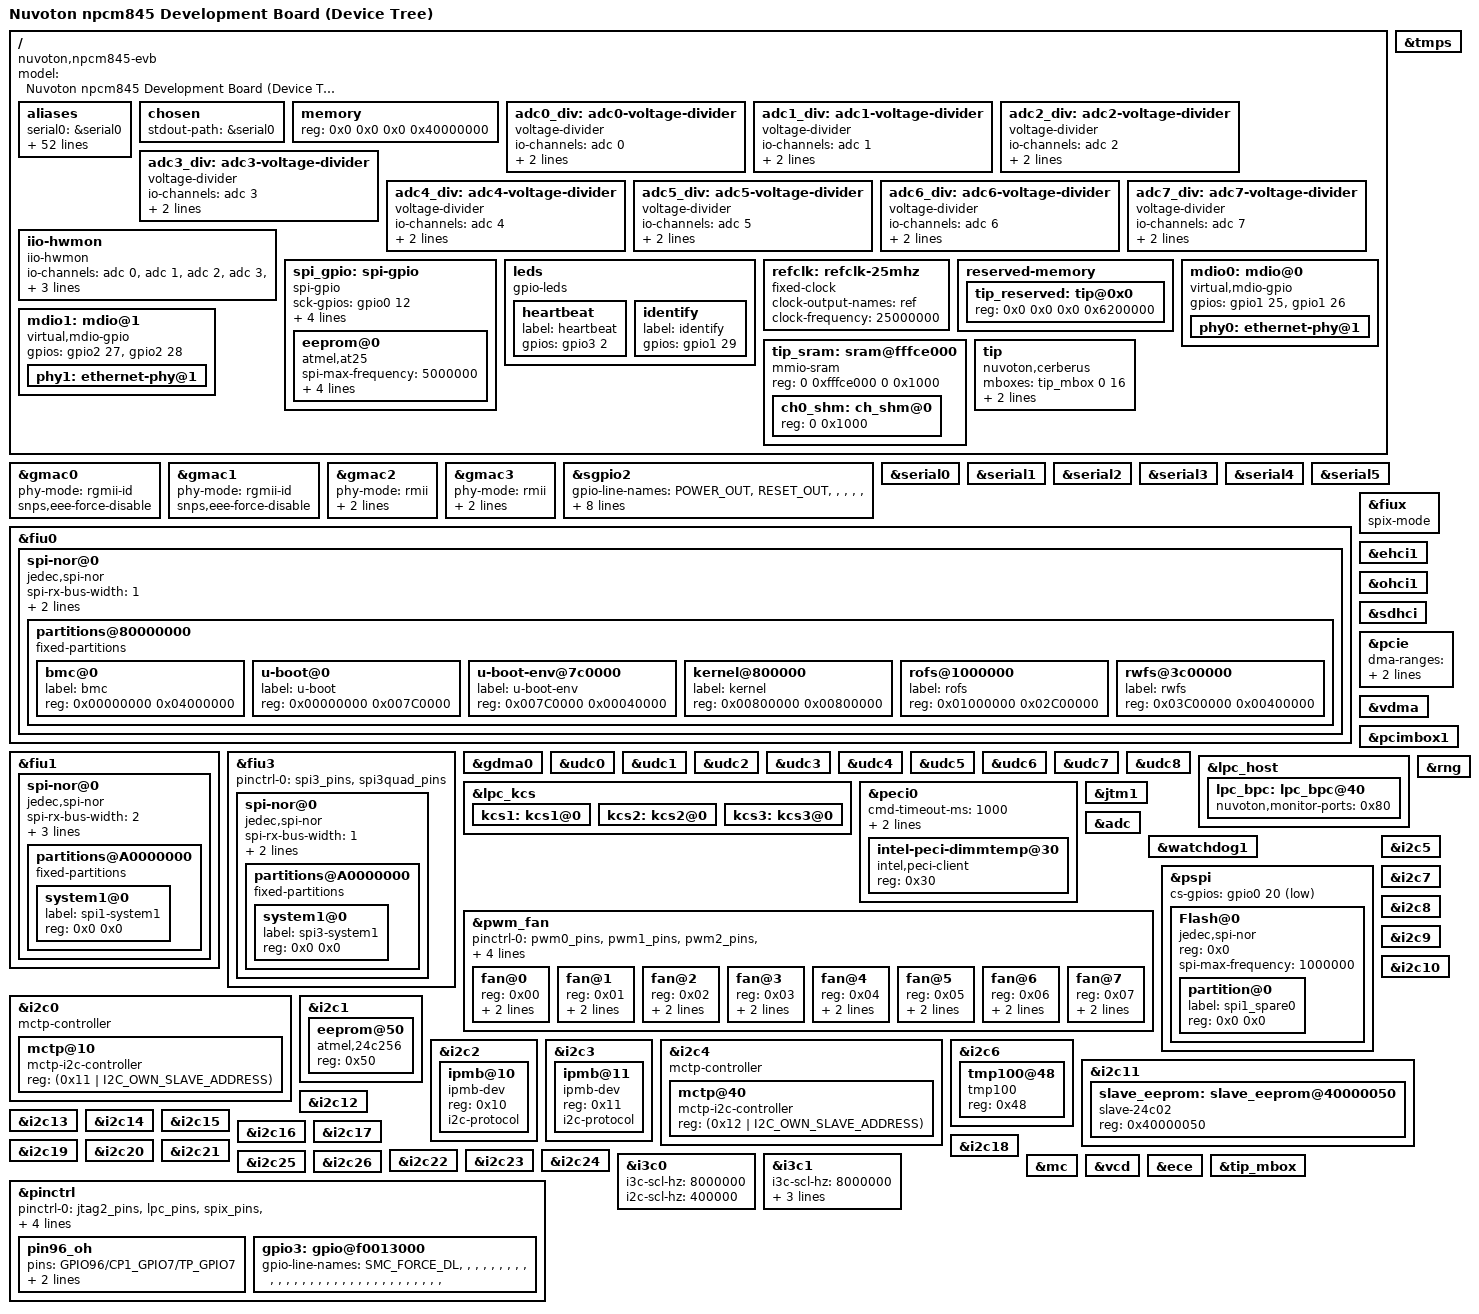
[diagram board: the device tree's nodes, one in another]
// SPDX-License-Identifier: GPL-2.0
// Copyright (c) 2021 Nuvoton Technology tomer.maimon@nuvoton.com

/dts-v1/;
#include "nuvoton-npcm845.dtsi"
#include "nuvoton-npcm845-pincfg-evb.dtsi"
#include <dt-bindings/i2c/i2c.h>

/ {
	model = "Nuvoton npcm845 Development Board (Device Tree)";
	compatible = "nuvoton,npcm845-evb", "nuvoton,npcm845";

	aliases {
		serial0 = &serial0;
		serial1 = &serial1;
		serial2 = &serial2;
		serial3 = &serial3;
		serial4 = &serial4;
		serial5 = &serial5;
		ethernet0 = &gmac0;
		ethernet1 = &gmac1;
		ethernet2 = &gmac2;
		ethernet3 = &gmac3;
		mdio-gpio0 = &mdio0;
		mdio-gpio1 = &mdio1;
		udc0 = &udc0;
		udc1 = &udc1;
		udc2 = &udc2;
		udc3 = &udc3;
		udc4 = &udc4;
		udc5 = &udc5;
		udc6 = &udc6;
		udc7 = &udc7;
		udc8 = &udc8;
		fiu0 = &fiu0;
		fiu1 = &fiu3;
		fiu2 = &fiux;
		fiu3 = &fiu1;
		i2c0 = &i2c0;
		i2c1 = &i2c1;
		i2c2 = &i2c2;
		i2c3 = &i2c3;
		i2c4 = &i2c4;
		i2c5 = &i2c5;
		i2c6 = &i2c6;
		i2c7 = &i2c7;
		i2c8 = &i2c8;
		i2c9 = &i2c9;
		i2c10 = &i2c10;
		i2c11 = &i2c11;
		i2c12 = &i2c12;
		i2c13 = &i2c13;
		i2c14 = &i2c14;
		i2c15 = &i2c15;
		i2c16 = &i2c16;
		i2c17 = &i2c17;
		i2c18 = &i2c18;
		i2c19 = &i2c19;
		i2c20 = &i2c20;
		i2c21 = &i2c21;
		i2c22 = &i2c22;
		i2c23 = &i2c23;
		i2c24 = &i2c24;
		i2c25 = &i2c25;
		i2c26 = &i2c26;
		spi1 = &spi_gpio;
	};

	chosen {
		stdout-path = &serial0;
	};

	memory {
		reg = <0x0 0x0 0x0 0x40000000>;
	};

	/*
	 * Voltage dividers for ADC channels.
	 * Adjust output-ohms and full-ohms according to your schematic.
	 * Formula: Vin = Vout × (full-ohms / output-ohms)
	 *
	 * Example: If R1 = 100K, R2 = 10K (10:1 divider)
	 *   output-ohms = 10000  (R2, resistor to GND)
	 *   full-ohms = 110000   (R1 + R2)
	 */
	adc0_div: adc0-voltage-divider {
		compatible = "voltage-divider";
		io-channels = <&adc 0>;
		io-channel-names = "parent";
		#io-channel-cells = <0>;
		output-ohms = <4700>;
		full-ohms = <104700>;
	};

	adc1_div: adc1-voltage-divider {
		compatible = "voltage-divider";
		io-channels = <&adc 1>;
		io-channel-names = "parent";
		#io-channel-cells = <0>;
		output-ohms = <10000>;
		full-ohms = <110000>;
	};

	adc2_div: adc2-voltage-divider {
		compatible = "voltage-divider";
		io-channels = <&adc 2>;
		io-channel-names = "parent";
		#io-channel-cells = <0>;
		output-ohms = <2000>;
		full-ohms = <12000>;
	};

	adc3_div: adc3-voltage-divider {
		compatible = "voltage-divider";
		io-channels = <&adc 3>;
		io-channel-names = "parent";
		#io-channel-cells = <0>;
		output-ohms = <4700>;
		full-ohms = <14700>;
	};

	adc4_div: adc4-voltage-divider {
		compatible = "voltage-divider";
		io-channels = <&adc 4>;
		io-channel-names = "parent";
		#io-channel-cells = <0>;
		output-ohms = <10000>;
		full-ohms = <14700>;
	};

	adc5_div: adc5-voltage-divider {
		compatible = "voltage-divider";
		io-channels = <&adc 5>;
		io-channel-names = "parent";
		#io-channel-cells = <0>;
		output-ohms = <10000>;
		full-ohms = <12000>;
	};

	adc6_div: adc6-voltage-divider {
		compatible = "voltage-divider";
		io-channels = <&adc 6>;
		io-channel-names = "parent";
		#io-channel-cells = <0>;
		output-ohms = <100000>;
		full-ohms = <110000>;
	};

	adc7_div: adc7-voltage-divider {
		compatible = "voltage-divider";
		io-channels = <&adc 7>;
		io-channel-names = "parent";
		#io-channel-cells = <0>;
		output-ohms = <100000>;
		full-ohms = <104700>;
	};

	iio-hwmon {
		compatible = "iio-hwmon";
		/* Use voltage-dividers to get real voltage values */
		io-channels = <&adc 0>, <&adc 1>, <&adc 2>, <&adc 3>,
			<&adc 4>, <&adc 5>, <&adc 6>, <&adc 7>,
			<&adc0_div>, <&adc1_div>, <&adc2_div>, <&adc3_div>,
			<&adc4_div>, <&adc5_div>, <&adc6_div>, <&adc7_div>;
	};

	spi_gpio: spi-gpio {
		compatible = "spi-gpio";
		#address-cells = <1>;
		#size-cells = <0>;
		sck-gpios = <&gpio0 12 GPIO_ACTIVE_HIGH>;
		mosi-gpios = <&gpio0 13 GPIO_ACTIVE_HIGH>;
		miso-gpios = <&gpio0 14 GPIO_ACTIVE_HIGH>;
		num-chipselects = <1>;
		cs-gpios = <&gpio0 15 GPIO_ACTIVE_LOW>;

		eeprom@0 {
			compatible = "atmel,at25";
			spi-max-frequency = <5000000>;
			size = <0x10000>;
			pagesize = <128>;
			reg = <0>;
			address-width = <16>;
		};
	};

	leds {
		compatible = "gpio-leds";
		heartbeat {
			label = "heartbeat";
			gpios = <&gpio3 2 GPIO_ACTIVE_HIGH>; /* gpio98 */
		};
		identify {
			label = "identify";
			gpios = <&gpio1 29 GPIO_ACTIVE_HIGH>; /* gpio61 */
		};
	};

	refclk: refclk-25mhz {
		compatible = "fixed-clock";
		clock-output-names = "ref";
		clock-frequency = <25000000>;
		#clock-cells = <0>;
	};

	reserved-memory {
		#address-cells = <2>;
		#size-cells = <2>;
		ranges;

		tip_reserved: tip@0x0 {
			reg = <0x0 0x0 0x0 0x6200000>;
		};

		/*linux,cma {
			compatible = "shared-dma-pool";
			reusable;
			size = <0x0 0x8000000>;
			alloc-ranges = <0x0 0x20000000 0x0 0x8000000>;
			linux,cma-default;
		};*/
	};


	mdio0: mdio@0 {
		compatible = "virtual,mdio-gpio";
		gpios = <&gpio1 25 GPIO_ACTIVE_HIGH>,
			<&gpio1 26 GPIO_ACTIVE_HIGH>; 
		#address-cells = <1>;
		#size-cells = <0>;

		phy0: ethernet-phy@1 {
		};
	};

	mdio1: mdio@1 {
		compatible = "virtual,mdio-gpio";
		gpios = <&gpio2 27 GPIO_ACTIVE_HIGH>, 
			<&gpio2 28 GPIO_ACTIVE_HIGH>; 
		#address-cells = <1>;
		#size-cells = <0>;

		phy1: ethernet-phy@1 {
		};
	};

	tip_sram: sram@fffce000 {
		compatible = "mmio-sram";
		reg = <0 0xfffce000 0 0x1000>;
		#address-cells = <1>;
		#size-cells = <1>;
		ranges = <0 0 0xfffce000 0x1000>;
		ch0_shm: ch_shm@0 {
			reg = <0 0x1000>;
		};
	};

	tip {
		compatible = "nuvoton,cerberus";
		mboxes = <&tip_mbox 0 16>; /*channel 0, 16th doorbell */
		mbox-names = "cerberus";
		shmem = <&ch0_shm>;
		status = "okay";
	};

};

&gmac0 {
	phy-mode = "rgmii-id";
	snps,eee-force-disable;
	status = "okay";
};

&gmac1 {
	phy-mode = "rgmii-id";
	snps,eee-force-disable;
	status = "okay";
};

&gmac2 {
	phy-mode = "rmii";
	pinctrl-names = "default";
	pinctrl-0 = <&r1_pins
			&r1oen_pins>;
	phy-handle = <&phy0>;
	status = "okay";
};

&gmac3 {
	phy-mode = "rmii";
	pinctrl-names = "default";
	pinctrl-0 = <&r2_pins
			&r2oen_pins>;
	phy-handle = <&phy1>;
	status = "okay";
};

&tmps {
	status = "okay";
};

&sgpio2 {
	status = "okay";
	gpio-line-names =
		"POWER_OUT","RESET_OUT","","","","","","NMI_OUT",
		"g_led","","","","","","","",
		"","","","","","","","",
		"","","","","","","","",
		"","","","","","","","",
		"","","","","","","","",
		"","","","","","","","",
		"","","","","","","","",
		"","","PS_PWROK","POST_COMPLETE","POWER_BUTTON","RESET_BUTTON","NMI_BUTTON","",
		"","","","","","","","",
		"","","","","","","","",
		"","","","","","","","",
		"","","","","","","","",
		"","","","","","","","",
		"","","","","","","","",
		"","","","","","","","";
};

&serial0 {
	status = "okay";
};

&serial1 {
	status = "okay";
};

&serial2 {
	status = "okay";
};

&serial3 {
	status = "okay";
};

&serial4 {
	status = "okay";
};

&serial5 {
	status = "okay";
};


&fiu0 {
	status = "okay";
	spi-nor@0 {
		compatible = "jedec,spi-nor";
		#address-cells = <1>;
		#size-cells = <1>;
		spi-rx-bus-width = <1>;
		reg = <0>;
		spi-max-frequency = <5000000>;
		partitions@80000000 {
			compatible = "fixed-partitions";
			#address-cells = <1>;
			#size-cells = <1>;
			bmc@0 {
				label = "bmc";
				reg = <0x00000000 0x04000000>;
				};
			u-boot@0 {
				label = "u-boot";
				reg = <0x00000000 0x007C0000>;
				};
			u-boot-env@7c0000 {
				label = "u-boot-env";
				reg = <0x007C0000 0x00040000>;
				};
			kernel@800000 {
				label = "kernel";
				reg = <0x00800000 0x00800000>;
				};
			rofs@1000000 {
				label = "rofs";
				reg = <0x01000000 0x02C00000>;
				};
			rwfs@3c00000 {
				label = "rwfs";
				reg = <0x03C00000 0x00400000>;
				};
		};
	};
};

&fiu1 {
	/*pinctrl-0 = <&spi1_pins>, <&spi1quad_pins>;*/
	status = "okay";
	spi-nor@0 {
		compatible = "jedec,spi-nor";
		#address-cells = <1>;
		#size-cells = <1>;
		spi-rx-bus-width = <2>;
		spi-tx-bus-width = <2>;
		reg = <0>;
		spi-max-frequency = <5000000>;
		partitions@A0000000 {
			compatible = "fixed-partitions";
			#address-cells = <1>;
			#size-cells = <1>;
			system1@0 {
				label = "spi1-system1";
				reg = <0x0 0x0>;
			};
		};
	};
};

&fiu3 {
	pinctrl-0 = <&spi3_pins>, <&spi3quad_pins>;
	status = "okay";
	spi-nor@0 {
		compatible = "jedec,spi-nor";
		#address-cells = <1>;
		#size-cells = <1>;
		spi-rx-bus-width = <1>;
		reg = <0>;
		spi-max-frequency = <5000000>;
		partitions@A0000000 {
			compatible = "fixed-partitions";
			#address-cells = <1>;
			#size-cells = <1>;
			system1@0 {
				label = "spi3-system1";
				reg = <0x0 0x0>;
			};
		};
	};
};

&fiux {
	spix-mode;
};

&ehci1 {
	status = "okay";
};

&ohci1 {
        status = "okay";
};

&sdhci {
	status = "okay";
};

&pcie {
	/* used for e1000e PCI -> AXI window opening */
	dma-ranges = <0x02000000 0 0x00000000 0x0 0x00000000 0 0x40000000>;
	npcm-pci-ep-rst = <&gpio3 24 1>;
	status = "okay";
};

&vdma {
	status = "okay";
};

&pcimbox1 {
	status = "okay";
};

&gdma0 {
	status = "okay";
};

&udc0 {
	status = "okay";
};

&udc1 {
	status = "okay";
};

&udc2 {
	status = "okay";
};

&udc3 {
	status = "okay";
};

&udc4 {
	status = "okay";
};

&udc5 {
	status = "okay";
};

&udc6 {
	status = "okay";
};

&udc7 {
	status = "okay";
};

&udc8 {
	status = "okay";
};

&lpc_kcs {
	kcs1: kcs1@0 {
		status = "okay";
	};

	kcs2: kcs2@0 {
		status = "okay";
	};

	kcs3: kcs3@0 {
		status = "okay";
	};
};

&lpc_host {
	lpc_bpc: lpc_bpc@40 {
		nuvoton,monitor-ports = <0x80>;
		status = "okay";
	};
};

&peci0 {
	cmd-timeout-ms = <1000>;
	npcm,pull-down = <0>;
	npcm,host-neg-bit-rate = <15>;
	#address-cells = <1>;
	#size-cells = <0>;
	status = "okay";
	intel-peci-dimmtemp@30 {
		compatible = "intel,peci-client";
		reg = <0x30>;
		status = "okay";
	};
};

&jtm1 {
	status = "okay";
};

&rng {
	status = "okay";
};

&adc {
	#io-channel-cells = <1>;
	status = "okay";
};

&watchdog1 {
	status = "okay";
};

&pwm_fan {
	status = "okay";
	pinctrl-names = "default";
	pinctrl-0 = <&pwm0_pins &pwm1_pins
		&pwm2_pins &pwm3_pins
		&pwm4_pins &pwm5_pins
		&pwm6_pins &pwm7_pins
		&fanin0_pins &fanin1_pins
		&fanin2_pins &fanin3_pins
		&fanin4_pins &fanin5_pins
		&fanin6_pins &fanin7_pins>;
	#address-cells = <1>;
	#size-cells = <0>;
	fan@0 {
		reg = <0x00>;
		fan-tach-ch = /bits/ 8 <0x00 0x01>;
		cooling-levels = <127 255>;
	};
	fan@1 {
		reg = <0x01>;
		fan-tach-ch = /bits/ 8 <0x02 0x03>;
		cooling-levels = /bits/ 8 <127 255>;
	};
	fan@2 {
		reg = <0x02>;
		fan-tach-ch = /bits/ 8 <0x04 0x05>;
		cooling-levels = /bits/ 8 <127 255>;
	};
	fan@3 {
		reg = <0x03>;
		fan-tach-ch = /bits/ 8 <0x06 0x07>;
		cooling-levels = /bits/ 8 <127 255>;
	};
	fan@4 {
		reg = <0x04>;
		fan-tach-ch = /bits/ 8 <0x08 0x09>;
		cooling-levels = /bits/ 8 <127 255>;
	};
	fan@5 {
		reg = <0x05>;
		fan-tach-ch = /bits/ 8 <0x0A 0x0B>;
		cooling-levels = /bits/ 8 <127 255>;
	};
	fan@6 {
		reg = <0x06>;
		fan-tach-ch = /bits/ 8 <0x0C 0x0D>;
		cooling-levels = /bits/ 8 <127 255>;
	};
	fan@7 {
		reg = <0x07>;
		fan-tach-ch = /bits/ 8 <0x0E 0x0F>;
		cooling-levels = /bits/ 8 <127 255>;
	};
};

&pspi {
	cs-gpios = <&gpio0 20 GPIO_ACTIVE_LOW>;
	status = "okay";
	Flash@0 {
		compatible = "jedec,spi-nor";
		reg = <0x0>;
		#address-cells = <1>;
		#size-cells = <1>;
		spi-max-frequency = <1000000>;
		partition@0 {
			label = "spi1_spare0";
			reg = <0x0 0x0>;
		};
	};
};

&i2c0 {
	status = "okay";
	mctp-controller;
	mctp@10 {
		compatible = "mctp-i2c-controller";
		reg = <(0x11 | I2C_OWN_SLAVE_ADDRESS)>;
	};
};

&i2c1 {
	status = "okay";
	#address-cells = <1>;
	#size-cells = <0>;
	eeprom@50 {
		compatible = "atmel,24c256";
		reg = <0x50>;
	};
};

&i2c2 {
	status = "okay";
	#address-cells = <1>;
	#size-cells = <0>;
	ipmb@10 {
		compatible = "ipmb-dev";
		reg = <0x10>;
		i2c-protocol;
	};
};

&i2c3 {
	status = "okay";
	#address-cells = <1>;
	#size-cells = <0>;
	ipmb@11 {
		compatible = "ipmb-dev";
		reg = <0x11>;
		i2c-protocol;
	};
};

&i2c4 {
	status = "okay";
	mctp-controller;
	mctp@40 {
		compatible = "mctp-i2c-controller";
		reg = <(0x12 | I2C_OWN_SLAVE_ADDRESS)>;
	};
};

&i2c5 {
	status = "okay";
};

&i2c6 {
	status = "okay";
	#address-cells = <1>;
	#size-cells = <0>;
	tmp100@48 {
		compatible = "tmp100";
		reg = <0x48>;
		status = "okay";
	};
};

&i2c7 {
	status = "okay";
};

&i2c8 {
	status = "okay";
};

&i2c9 {
	status = "okay";
};

&i2c10 {
	status = "okay";
};

&i2c11 {
	status = "okay";
	slave_eeprom:slave_eeprom@40000050 {
		compatible = "slave-24c02";
		reg = <0x40000050>;
		status = "okay";
	};
	
};

&i2c12 {
	status = "okay";
};

&i2c13 {
	status = "okay";
};

&i2c14 {
	status = "okay";
};

&i2c15 {
	status = "okay";
};

&i2c16 {
	status = "okay";
};

&i2c17 {
	status = "okay";
};

&i2c18 {
	status = "okay";
};

&i2c19 {
	status = "okay";
};

&i2c20 {
	status = "okay";
};

&i2c21 {
	status = "okay";
};

&i2c22 {
	status = "okay";
};

&i2c23 {
	status = "okay";
};

&i2c24 {
	status = "okay";
};

&i2c25 {
	status = "okay";
};

&i2c26 {
	status = "okay";
};

&i3c0 {
	status = "okay";
	i3c-scl-hz = <8000000>;
	i2c-scl-hz = <400000>;
};

&i3c1 {
	status = "okay";
	i3c-scl-hz = <8000000>;
	i2c-scl-hz = <400000>;
	dmas = <&gdma0 0>, <&gdma0 1>;
	dma-names = "tx", "rx";
	mctp-controller;
};

&mc {
	status = "okay";
};

&pinctrl {
	pinctrl-names = "default";
	pinctrl-0 = <
			&jtag2_pins
			&lpc_pins
			&spix_pins
			&pin0_slew
			&pin1_slew
			&pin2_slew
			&pin3_slew
			&pin4_slew
			&pin5_slew
			&pin6_slew
			&pin7_slew
			&pin17_slew
			&pin18_slew
			&pin19_slew
			&pin108_slew
			&pin109_slew
			&pin96_oh>;

		pin96_oh: pin96_oh {
			pins = "GPIO96/CP1_GPIO7/TP_GPIO7";
			bias-disable;
			output-high;
		};

		gpio3: gpio@f0013000 {
			/* SMC_FORCE_DL=gpio96 */
			gpio-line-names =
			/*96-127*/
			"SMC_FORCE_DL","","","","","","","",
			"","","","","","","","",
			"","","","","","","","",
			"","","","","","","","";
		};
};

&vcd {
	status = "okay";
};

&ece {
	status = "okay";
};

&tip_mbox {
	status = "okay";
};
